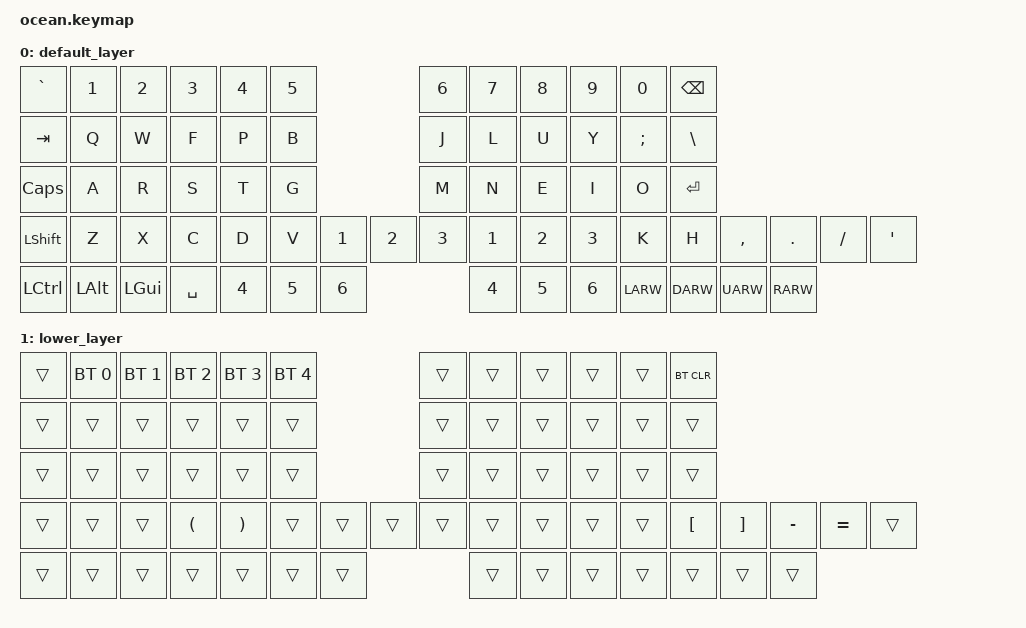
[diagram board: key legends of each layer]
/*
 * Copyright (c 2020 The ZMK Contributors
 *
 * SPDX-License-Identifier: MIT
 */

#include <behaviors.dtsi>
#include <dt-bindings/zmk/keys.h>
#include <dt-bindings/zmk/bt.h>

/ {
        keymap {
                compatible = "zmk,keymap";

                default_layer {
// ---------------------------------------------------------------------------------
// |   `  |  1  |  2  |  3  |  4  |  5  |     |  6  |  7  |  8  |  9  |  0  | BKSP |
// |  TAB |  Q  |  W  |  E  |  R  |  T  |     |  Y  |  U  |  I  |  O  |  P  |  \   |
// | CAPS |  A  |  S  |  D  |  F  |  G  |     |  H  |  J  |  K  |  L  |  ;  |  ENT |
// | SHFT |  Z  |  X  |  C  |  V  |  B  | ?     |  N  |  M  |  ,  |  .  |  /  | APOS |
// | CTRL | ALT | GUI | SPC | SPC | SPC |     | SPC | LOW |LARW |DARW |UARW | RARW |

// `            1       2       3       4       5                               6       7       8       9       0       ??
// tab          Q       W       F       P       B                               J       L       U       Y       ;       ??
// caps         A       R       S       T       G                               M       N       E       I       O       ??
// LSHIFT       Z       X       C       D       V  (??  SPACE  &lt1)  (&lt1  SPACE  ??)   K        H       ,       .       /      ??
// LCTRL        LALT    ??      ??      (??      ??      ??)            (??    ??      ??)      ??      ??      ??      ??
                        bindings = <
   &kp GRAVE  &kp N1    &kp N2    &kp N3     &kp N4     &kp N5               &kp N6     &kp N7  &kp N8     &kp N9    &kp N0    &kp BSPC
   &kp TAB    &kp Q     &kp W     &kp F      &kp P      &kp B                &kp J      &kp L   &kp U      &kp Y     &kp SEMI     &kp BSLH
   &kp CAPS   &kp A     &kp R     &kp S      &kp T      &kp G                &kp M      &kp N   &kp E      &kp I     &kp O  &kp RET
   &kp LSHFT  &kp Z     &kp X     &kp C      &kp D      &kp V &kp N1 &kp N2 &kp N3             &kp N1 &kp N2 &kp N3 &kp K      &kp H   &kp COMMA  &kp DOT   &kp FSLH  &kp APOS
   &kp LCTRL  &kp LALT  &kp LGUI  &kp SPACE                   &kp N4 &kp N5 &kp N6             &kp N4 &kp N5  &kp N6   &kp LARW   &kp DARW  &kp UARW  &kp RARW
                        >;
                };
                lower_layer {
// ------------------------------------------------------------------------------------------------------------
// |       |  BT1  |  BT2  |  BT3  |  BT4  |  BT5  |          |       |       |       |       |       | BTCLR |
// |       |       |       |       |       |       |          |       |       |       |       |       |       |
// |       |       |       | LPAR  | RPAR  |       |          |       | LBKT  | RBKT  |       |       |       |
// |       |       |       |       |       |       |          |       |       |       |       |       |       |
                        bindings = <
   &trans    &bt BT_SEL 0   &bt BT_SEL 1   &bt BT_SEL 2   &bt BT_SEL 3   &bt BT_SEL 4           &trans    &trans    &trans   &trans   &trans  &bt BT_CLR
   &trans    &trans         &trans         &trans         &trans         &trans                 &trans    &trans    &trans   &trans   &trans  &trans
   &trans    &trans         &trans         &trans         &trans         &trans                 &trans    &trans    &trans   &trans   &trans  &trans
   &trans    &trans         &trans         &kp LPAR       &kp RPAR       &trans &trans &trans &trans                 &trans &trans &trans&trans    &kp LBKT  &kp RBKT &kp MINUS   &kp EQUAL  &trans
   &trans    &trans         &trans         &trans         &trans         &trans &trans                 &trans &trans    &trans    &trans   &trans   &trans  &trans
                        >;
                };
        };
};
